# SERDES_10G0 register map
Vendor: Texas Instruments
Registers are 32-bit, read-write, reset 0x0 unless marked. A register's access mark holds for its fields unless they carry their own. Offsets are as the file gives them; [hi:lo] are bit positions; {n}, {i} and the like mark numbered series.

## SERDES_10G0 (part 5 of 5)
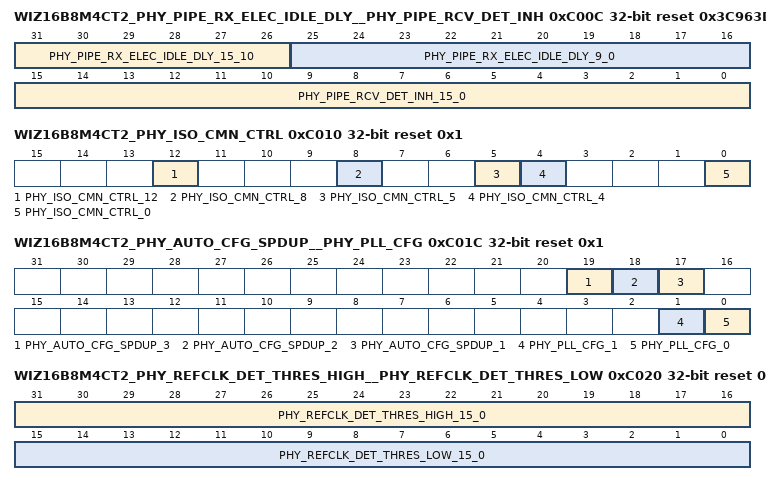
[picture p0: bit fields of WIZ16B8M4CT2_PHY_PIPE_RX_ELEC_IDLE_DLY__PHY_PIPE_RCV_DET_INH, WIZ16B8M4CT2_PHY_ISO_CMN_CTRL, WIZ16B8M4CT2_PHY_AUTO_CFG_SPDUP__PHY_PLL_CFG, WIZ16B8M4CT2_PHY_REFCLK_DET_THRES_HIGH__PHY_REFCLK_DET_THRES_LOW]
0xC00C WIZ16B8M4CT2_PHY_PIPE_RX_ELEC_IDLE_DLY__PHY_PIPE_RCV_DET_INH reset 0x3C963D09 — PIPE receiver detect inhibit register ()
  [31:26] PHY_PIPE_RX_ELEC_IDLE_DLY_15_10 — PCIe PCS L1.x exit Rx electrical idle force fast count : Counter load value to hold PIPE Rx Electrical Idle high upon exit from L1.x. Counter is loaded and starts counting down after phy_l*_rx_elec_idle_det_en is asserted high. Default is 500 nsec. This counter accounts for time to power on just the analog Rx signal detect block. Based on reference clock cycles (25 MHz default). Minimum value = 6'd0.
  [25:16] PHY_PIPE_RX_ELEC_IDLE_DLY_9_0 — PCIe PCS L1.x exit Rx electrical idle force full count : Counter load value to hold PIPE Rx Electrical Idle high upon exit from L1.x when the PMA common was powered down. Counter is loaded and starts counting down upon de-assertion of PMA cmn_ref_clk_disable (upon de-assertion of phy_l*_ent_l1_x for first link). Default is 6 usec. This counter accounts for time to power on the bias and decap and only takes effect if the PMA was suspended. Based on reference clock cycles (25 MHz default). Minimum value = 10'd1.
  [15:0] PHY_PIPE_RCV_DET_INH_15_0 — PCS Receiver Detect Inhibit Counter Load Value: Counter load value to delay receiver detection request to PMA until PMA common mode is within the required range. The timer (running on divided reference clock from PMA) starts once the PMA common has completed startup. If receiver detect request is received while timer has not expired, the PCS will wait until the timer expires before signaling the request to the PMA. Load value is specified in multiples of 4x the divider reference clock period (typically 40 nsec for 100 MHz reference clock input frequency) for a 2.5 msec inhibit time.
0xC010 WIZ16B8M4CT2_PHY_ISO_CMN_CTRL access per field reset 0x1 — PHY common control signal isolation register ()
  [12] PHY_ISO_CMN_CTRL_12 ro — Current value of phy_refclk_reqd PHY output.
  [8] PHY_ISO_CMN_CTRL_8 rw — Drives phy_refclk_en PHY input when in PHY macro and PMA isolation mode.
  [5] PHY_ISO_CMN_CTRL_5 rw — Drives phy_pma_suspend_override PHY input when in PHY macro and PMA isolation mode.
  [4] PHY_ISO_CMN_CTRL_4 rw — Drives refclk_rcvr_pwrdn internal PHY signal when in PHY macro and PMA isolation mode (1 = powers down the reference clock receiver). During normal operation, refclk_rcvr_pwrdn is driven from ~abp_preset_n, which powers down the reference clock receiver when the PHY is disabled.
  [0] PHY_ISO_CMN_CTRL_0 rw — Drives phy_reset_n PHY input when in PHY macro and PMA isolation mode.
0xC014 WIZ16B8M4CT2_PHY_STATE_CHG_TIMEOUT reset 0x30D4 — PHY state change monitor timeout
  [15:0] PHY_STATE_CHG_TIMEOUT_15_0 — State change timeout: Bits [19:4] of the state change timeout (bits [3:0] are zero). The timeout is the maximum number of APB clock cycles (abp_pclk) that are allowed for completion of a PHY power state change for the link. If the timeout expires, phy_interrupt_ln_XX for the associated lane is asserted and interrupt status register bit is set. For maximum allowed APB clock frequency, this provides 5.2 msec maximum timeout. Default is set for 1 msec for the maximum APB clock frequency.
0xC01C WIZ16B8M4CT2_PHY_AUTO_CFG_SPDUP__PHY_PLL_CFG access per field reset 0x1 — PHY speedup control register
  [19] PHY_AUTO_CFG_SPDUP_3 ro — Speedup configuration complete: 1 = PHY speedup configuration is complete, 0 = not complete.
  [18] PHY_AUTO_CFG_SPDUP_2 rw — Speedup configuration stall: 1 = upon completion of PHY speedup configuration, do not release reset to PMA until this bit is cleared, 0 = release reset to PMA upon completion of PHY speedup configuration. Do not set high when [1] = 0.
  [17] PHY_AUTO_CFG_SPDUP_1 rw — Speedup configuration enable: If set to 1 upon de-assertion (high) of phy_reset_n, the PHY will be configured for simulation speedup. Only for use in RTL or gate-level simulations. Not for use in silicon.
  [1] PHY_PLL_CFG_1 rw — PLL configuration: 0 = PHY configured to only use PLL0 / PLL1 disabled. 1 = PHY configured to use both PLL0 and PLL1.
  [0] PHY_PLL_CFG_0 rw — Single link PCIe configuration : 1 = PHY configured such that there is only a single PCIe link (1xN) and all PCIe rates will be driven by PLL0. Any other links are not PCIe and will not use PLL0. 0 = ALl other configurations. This is a static configuration, which can only be changed while phy_reset_n is asserted low.
0xC020 WIZ16B8M4CT2_PHY_REFCLK_DET_THRES_HIGH__PHY_REFCLK_DET_THRES_LOW reset 0x274201C2 — PHY external reference clock detect low threshold register
  [31:16] PHY_REFCLK_DET_THRES_HIGH_15_0 — External Reference Clock Active Detect High Threshold: This is the maximum number of external reference clock cycles which must be counted during the measurement interval to indicate a valid clock detected. The default value is based on 100MHz reference clock frequency and 10 MHZ apb_pclk frequency.
  [15:0] PHY_REFCLK_DET_THRES_LOW_15_0 — External Reference Clock Active Detect Low Threshold: This is the minimum number of external reference clock cycles which must be counted during the measurement interval to indicate a valid clock detected. The default value is based on 100MHz reference clock external frequency and 200 MHz (max) apb_pclk frequency.
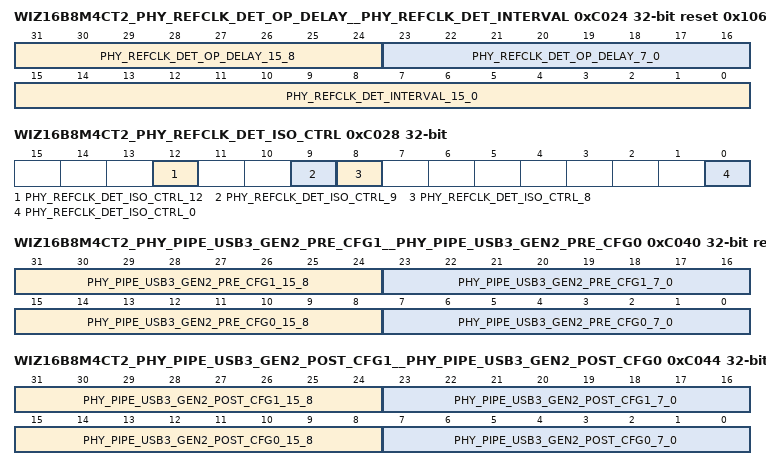
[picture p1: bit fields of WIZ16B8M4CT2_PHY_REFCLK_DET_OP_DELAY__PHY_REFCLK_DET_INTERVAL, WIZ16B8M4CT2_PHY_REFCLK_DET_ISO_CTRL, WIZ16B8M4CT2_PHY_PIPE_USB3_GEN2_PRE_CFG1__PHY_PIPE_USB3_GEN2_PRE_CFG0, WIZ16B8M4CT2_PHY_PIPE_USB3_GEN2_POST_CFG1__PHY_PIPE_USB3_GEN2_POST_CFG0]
0xC024 WIZ16B8M4CT2_PHY_REFCLK_DET_OP_DELAY__PHY_REFCLK_DET_INTERVAL reset 0x106403E8 — PHY external reference clock detect measurement interval register
  [31:24] PHY_REFCLK_DET_OP_DELAY_15_8 — External Reference Clock Active Detect End Delay: This is the number of apb_pclk cycles to wait upon completion of measurement interval before capturing the result (accounts for synchronization delays).
  [23:16] PHY_REFCLK_DET_OP_DELAY_7_0 — External Reference Clock Active Detect Start Delay: This is the number of apb_pclk cycles to wait prior to start of measurement interval (accounts for enable delay of reference clock in PMA).
  [15:0] PHY_REFCLK_DET_INTERVAL_15_0 — External Reference Clock Active Detect Measurement Interval: This is the number of apb_pclk cycles in which to count external reference clock cycles. The default corresponds to 5 us for 200 MHz apb_clk and 100 us for 10 MHz apb_clock.
0xC028 WIZ16B8M4CT2_PHY_REFCLK_DET_ISO_CTRL access per field — PHY external reference clock detect isolation control register
  [12] PHY_REFCLK_DET_ISO_CTRL_12 ro — Captures the current value of the pma_cmn_ext_refclk_detected_cfg PHY input.
  [9] PHY_REFCLK_DET_ISO_CTRL_9 ro — Current value of pma_cmn_ext_refclk_detected PHY output.
  [8] PHY_REFCLK_DET_ISO_CTRL_8 ro — Current value of pma_cmn_ext_refclk_detected_valid PHY output.
  [0] PHY_REFCLK_DET_ISO_CTRL_0 wo — External Reference Clock Active Detect Start: Write with 1 to initiate an external reference clock active detect operation. Any previous operation must have completed prior to writing with 1.
0xC040 WIZ16B8M4CT2_PHY_PIPE_USB3_GEN2_PRE_CFG1__PHY_PIPE_USB3_GEN2_PRE_CFG0 reset 0xA0A — PHY USB3 Gen 2 pre-shoot configuration 0 register ()
  [31:24] PHY_PIPE_USB3_GEN2_PRE_CFG1_15_8 — USB3 Gen 2 transmit pre-shoot multiplier configuration 3: For a lane configured for USB3 mode at Gen 3 data rate, sets the multiplier configuration for the Tx de-emphasis pre-shoot (C-1) when pipe_lXX_tx_deemphasis[1:0] == 0b11 for the associated lane. Default: 0.
  [23:16] PHY_PIPE_USB3_GEN2_PRE_CFG1_7_0 — USB3 Gen 2 transmit pre-shoot multiplier configuration 2: For a lane configured for USB3 mode at Gen 3 data rate, sets the multiplier configuration for the Tx de-emphasis pre-shoot (C1) when pipe_lXX_tx_deemphasis[1:0] == 0b10 for the associated lane. Default: 0.
  [15:8] PHY_PIPE_USB3_GEN2_PRE_CFG0_15_8 — USB3 Gen 2 transmit pre-shoot multiplier configuration 1: For a lane configured for USB3 mode at Gen 3 data rate, sets the multiplier configuration for the Tx de-emphasis pre-shoot (C-1) when pipe_lXX_tx_deemphasis[1:0] == 0b01 for the associated lane. Default: 5/64.
  [7:0] PHY_PIPE_USB3_GEN2_PRE_CFG0_7_0 — USB3 Gen 2 transmit pre-shoot multiplier configuration 0: For a lane configured for USB3 mode at Gen 3 data rate, sets the multiplier configuration for the Tx de-emphasis pre-shoot (C-1) when pipe_lXX_tx_deemphasis[1:0] == 0b00 for the associated lane. The multiplier is set based on: Default: 5/64.
0xC044 WIZ16B8M4CT2_PHY_PIPE_USB3_GEN2_POST_CFG1__PHY_PIPE_USB3_GEN2_POST_CFG0 reset 0x101000 — PHY USB3 Gen 2 de-emphasis configuration 0 register ()
  [31:24] PHY_PIPE_USB3_GEN2_POST_CFG1_15_8 — USB3 Gen 2 transmit pre-shoot multiplier configuration 3: For a lane configured for USB3 mode at Gen 3 data rate, sets the multiplier configuration for the Tx de-emphasis (C1) when pipe_lXX_tx_deemphasis[1:0] == 0b11 for the associated lane. Default: 0.
  [23:16] PHY_PIPE_USB3_GEN2_POST_CFG1_7_0 — USB3 Gen 2 transmit pre-shoot multiplier configuration 2: For a lane configured for USB3 mode at Gen 3 data rate, sets the multiplier configuration for the Tx de-emphasis (C1) when pipe_lXX_tx_deemphasis[1:0] == 0b10 for the associated lane. Default: 1/8.
  [15:8] PHY_PIPE_USB3_GEN2_POST_CFG0_15_8 — USB3 Gen 2 transmit pre-shoot multiplier configuration 1: For a lane configured for USB3 mode at Gen 3 data rate, sets the multiplier configuration for the Tx de-emphasis (C1) when pipe_lXX_tx_deemphasis[1:0] == 0b01 for the associated lane. Default: 1/8.
  [7:0] PHY_PIPE_USB3_GEN2_POST_CFG0_7_0 — USB3 Gen 2 transmit pre-shoot multiplier configuration 0: For a lane configured for USB3 mode at Gen 3 data rate, sets the multiplier configuration for the Tx de-emphasis (C1) when pipe_lXX_tx_deemphasis[1:0] == 0b00 for the associated lane. Default: 0.
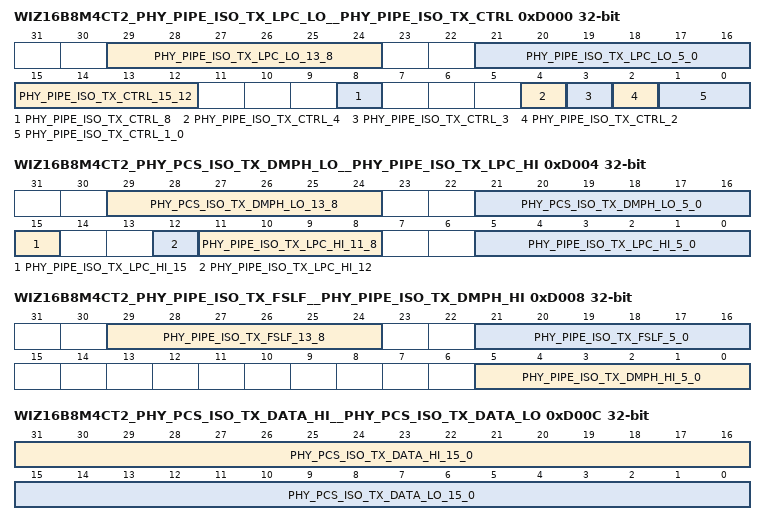
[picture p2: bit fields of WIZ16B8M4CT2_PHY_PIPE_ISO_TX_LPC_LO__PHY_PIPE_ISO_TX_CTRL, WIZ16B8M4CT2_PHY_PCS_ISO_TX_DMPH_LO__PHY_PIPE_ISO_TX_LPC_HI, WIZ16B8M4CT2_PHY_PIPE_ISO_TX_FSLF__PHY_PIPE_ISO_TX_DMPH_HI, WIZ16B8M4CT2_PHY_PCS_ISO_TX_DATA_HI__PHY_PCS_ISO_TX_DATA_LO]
0xD000 WIZ16B8M4CT2_PHY_PIPE_ISO_TX_LPC_LO__PHY_PIPE_ISO_TX_CTRL access per field — PIPE TX control signal isolation register ()
  [29:24] PHY_PIPE_ISO_TX_LPC_LO_13_8 ro — Current value of pipe_tx_local_tx_preset_coefficients[11:6] for the associated lane when PHY_PCS_ISO_TX_LPC_HI[15] == 1. Otherwise, 0.
  [21:16] PHY_PIPE_ISO_TX_LPC_LO_5_0 ro — Current value of pipe_tx_local_tx_preset_coefficients[5:0] for the associated lane when PHY_PCS_ISO_TX_LPC_HI[15] == 1. Otherwise, 0.
  [15:12] PHY_PIPE_ISO_TX_CTRL_15_12 rw — Drives pipe_tx_data_k PHY input for the associated lane when in PHY macro and PMA isolation modes.
  [8] PHY_PIPE_ISO_TX_CTRL_8 rw — Drives pipe_tx_ones_zeros input for the associated lane when in PHY macro and PMA isolation modes.
  [4] PHY_PIPE_ISO_TX_CTRL_4 rw — Drives pipe_tx_elec_idle PHY input for the associated lane when in PHY macro and PMA isolation modes
  [3] PHY_PIPE_ISO_TX_CTRL_3 rw — Drives pipe_tx_128b_enc_byp PHY input for the associated lane when in PHY macro and PMA isolation modes.
  [2] PHY_PIPE_ISO_TX_CTRL_2 rw — Drives pipe_tx_compliance PHY input for the associated lane when in PHY macro and PMA isolation modes.
  [1:0] PHY_PIPE_ISO_TX_CTRL_1_0 rw — Drives pipe_tx_pattern PHY input for the associated lane when in PHY macro and PMA isolation modes.
0xD004 WIZ16B8M4CT2_PHY_PCS_ISO_TX_DMPH_LO__PHY_PIPE_ISO_TX_LPC_HI access per field — PIPE TX local preset coefficients high isolation register ()
  [29:24] PHY_PCS_ISO_TX_DMPH_LO_13_8 rw — Drives pipe_tx_deemph[11:6] PHY input for the associated lane when in PHY macro and PMA isolation mode.
  [21:16] PHY_PCS_ISO_TX_DMPH_LO_5_0 rw — Drives pipe_tx_deemph[5:0] PHY input for the associated lane when in PHY macro and PMA isolation mode.
  [15] PHY_PIPE_ISO_TX_LPC_HI_15 ro — Set upon assertion of pipe_tx_local_tx_coeff_vld PHY output for the associated lane. Cleared upon writing PHY_PCS_ISO_TX_LPC_HI[12] with a 0.
  [12] PHY_PIPE_ISO_TX_LPC_HI_12 rw — Drives pipe_tx_get_local_preset_coef PHY output for the associated lane when in PHY macro and PMA isolation modes
  [11:8] PHY_PIPE_ISO_TX_LPC_HI_11_8 rw — Drives pipe_tx_local_preset_index PHY output for the associated lane when in PHY macro and PMA isolation modes.
  [5:0] PHY_PIPE_ISO_TX_LPC_HI_5_0 ro — Current value of pipe_tx_local_tx_preset_coefficients[17:12] for the associated lane when PHY_PCS_ISO_TX_LPC_HI[15] == 1. Otherwise, 0.
0xD008 WIZ16B8M4CT2_PHY_PIPE_ISO_TX_FSLF__PHY_PIPE_ISO_TX_DMPH_HI access per field — PIPE TX deemphasis high isolation register ()
  [29:24] PHY_PIPE_ISO_TX_FSLF_13_8 ro — Current value of pipe_tx_local_fs PHY output for the associated lane. (Not re-synchronized to apb_pclk)
  [21:16] PHY_PIPE_ISO_TX_FSLF_5_0 ro — Current value of pipe_tx_local_lf PHY output for the associated lane. (Not re-synchronized to apb_pclk)
  [5:0] PHY_PIPE_ISO_TX_DMPH_HI_5_0 rw — Drives pipe_tx_deemph[17:12] PHY input for the associated lane when in PHY macro and PMA isolation modes.
0xD00C WIZ16B8M4CT2_PHY_PCS_ISO_TX_DATA_HI__PHY_PCS_ISO_TX_DATA_LO — PCS TX PIPE data low isolation register ()
  [31:16] PHY_PCS_ISO_TX_DATA_HI_15_0 — Drives pipe_tx_data[31:16] PHY input for the associated lane when in PHY macro and PMA isolation mode.
  [15:0] PHY_PCS_ISO_TX_DATA_LO_15_0 — Drives pipe_tx_data[15:0] PHY input for the associated lane when in PHY macro and PMA isolation mode.
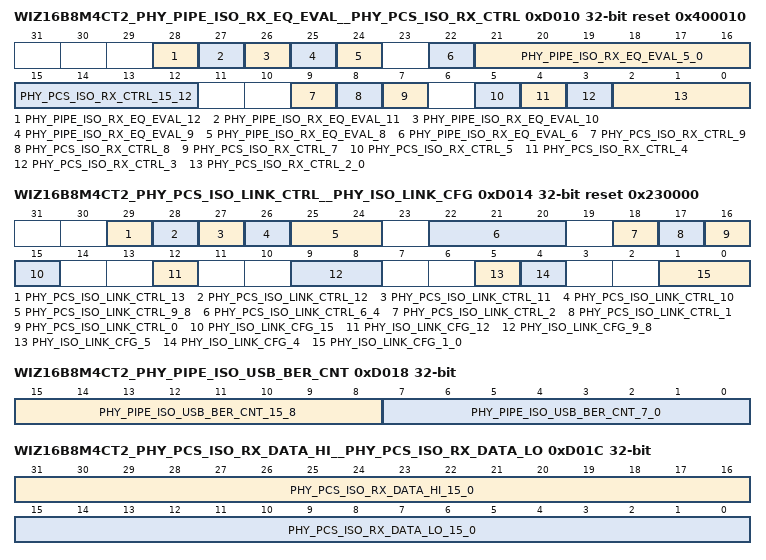
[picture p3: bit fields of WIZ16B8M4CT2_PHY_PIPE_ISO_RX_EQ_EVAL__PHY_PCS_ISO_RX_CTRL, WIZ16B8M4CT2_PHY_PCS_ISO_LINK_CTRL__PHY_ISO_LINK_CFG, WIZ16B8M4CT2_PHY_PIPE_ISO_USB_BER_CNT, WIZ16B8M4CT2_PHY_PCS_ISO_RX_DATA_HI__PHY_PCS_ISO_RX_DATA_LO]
0xD010 WIZ16B8M4CT2_PHY_PIPE_ISO_RX_EQ_EVAL__PHY_PCS_ISO_RX_CTRL access per field reset 0x400010 — PCS RX control signal isolation register ()
  [28] PHY_PIPE_ISO_RX_EQ_EVAL_12 rw — Drives pipe_invalid_request for the associated lane when in PHY macro and PMA isolation modes.
  [27] PHY_PIPE_ISO_RX_EQ_EVAL_11 rw — pipe_link_eval_dir_change[5:4] bit reversal enable. When low, no bit reversal. When high, the bit positions for pipe_link_eval_dir_change[5:4] PHY output for the associated lane are reversed.
  [26] PHY_PIPE_ISO_RX_EQ_EVAL_10 rw — pipe_link_eval_dir_change[3:2] bit reversal enable. When low, no bit reversal. When high, the bit positions for pipe_link_eval_dir_change[3:2] PHY output for the associated lane are reversed.
  [25] PHY_PIPE_ISO_RX_EQ_EVAL_9 rw — pipe_link_eval_dir_change[1:0] bit reversal enable. When low, no bit reversal. When high, the bit positions for pipe_link_eval_dir_change[1:0] PHY output for the associated lane are reversed.]
  [24] PHY_PIPE_ISO_RX_EQ_EVAL_8 rw — Drives pipe_rx_eval PHY input for the associated lane when in PHY macro and PMA isolation modes.
  [22] PHY_PIPE_ISO_RX_EQ_EVAL_6 ro — Captures pipe_phy_status for Rx equalization evaluation PHY output for the associated lane (does not include power state change signaling). Set when pipe_phy_status is high and pipe_rx_eq_eval to the PCS is high (i.e. after the isolation MUX). Cleared upon read.
  [21:16] PHY_PIPE_ISO_RX_EQ_EVAL_5_0 ro — pipe_link_eval_dir_change PHY output for the associated lane (prior to bit reversal logic) upon completion of Rx equalization evaluation. Captured upon assertion of Rx equalization eval pipe_phy_status when pipe_rx_eq_eval to the PCS (i.e. after the isolation MUX) is high. Cleared upon read. (Not re-synchronized to apb_pclk)
  [15:12] PHY_PCS_ISO_RX_CTRL_15_12 ro — Current value of pipe_rx_data_k PHY output for the associated lane, when PHY_PCS_ISO_RX_CTRL[5] == 1. Otherwise, 0. (Not re-synchronized to apb_pclk)
  [9] PHY_PCS_ISO_RX_CTRL_9 rw — Drives pipe_rx_eq_training PHY input for the associated lane when in PHY macro and PMA isolation modes.
  [8] PHY_PCS_ISO_RX_CTRL_8 rw — Drives pipe_rx_termination PHY input for the associated lane when in PHY macro and PMA isolation modes.
  [7] PHY_PCS_ISO_RX_CTRL_7 rw — Drives pipe_rx_polarity PHY input for the associated lane when in PHY macro and PMA isolation modes.
  [5] PHY_PCS_ISO_RX_CTRL_5 ro — Current value of pipe_rx_valid PHY output for the associated lane.
  [4] PHY_PCS_ISO_RX_CTRL_4 ro — Current value of pipe_rx_elec_idle PHY output for the associated lane.
  [3] PHY_PCS_ISO_RX_CTRL_3 ro — Current value of pipe_align_detect PHY output for the associated lane.
  [2:0] PHY_PCS_ISO_RX_CTRL_2_0 ro — Current value of pipe_rx_status PHY output for the associated lane. Holds the highest priority pipe_rx_status value seen, since the last register read. Cleared upon read.
0xD014 WIZ16B8M4CT2_PHY_PCS_ISO_LINK_CTRL__PHY_ISO_LINK_CFG access per field reset 0x230000 — PHY link configuration isolation register
  [29] PHY_PCS_ISO_LINK_CTRL_13 ro — Current value of phy_l*_ack_l1_x PHY output for the associated lane. ()
  [28] PHY_PCS_ISO_LINK_CTRL_12 rw — Drives the phy_l*_ent_l1_x PHY input for the associated lane when in PHY macro and PMA isolation modes. (Link signal - for multi-lane links, master lane used for all lanes in link.)
  [27] PHY_PCS_ISO_LINK_CTRL_11 rw — Drives the phy_l*_rx_elec_idle_det_en PHY input for the associated lane when in PHY macro and PMA isolation modes. (Link signal - for multi-lane links, master lane used for all lanes in link.)
  [26] PHY_PCS_ISO_LINK_CTRL_10 rw — Drives the phy_l*_tx_cmn_mode_en PHY input for the associated lane when in PHY macro and PMA isolation modes. (Link signal - for multi-lane links, master lane used for all lanes in link.)
  [25:24] PHY_PCS_ISO_LINK_CTRL_9_8 rw — Drives the pipe_l*_rate PHY input for the associated lane when in PHY macro and PMA isolation modes. (Link signal - for multi-lane links, master lane used for all lanes in link.)
  [22:20] PHY_PCS_ISO_LINK_CTRL_6_4 rw — Drives the pipe_l*_powerdown PHY input for the associated lane when in PHY macro and PMA isolation modes. (Link signal - for multi-lane links, master lane used for all lanes in link.)
  [18] PHY_PCS_ISO_LINK_CTRL_2 rw — Drives the pipe_l*_tx_det_rx_lpbk PHY input for the associated lane when in PHY macro and PMA isolation modes. (Link signal - for multi-lane links, master lane used for all lanes in link.)
  [17] PHY_PCS_ISO_LINK_CTRL_1 ro — Captures pipe_l*_phy_status (for power state and rate change) PHY output for the associated lane. Set when pipe_phy_status is high and cleared upon read if pipe_phy_status is low. ()
  [16] PHY_PCS_ISO_LINK_CTRL_0 rw — Drives the phy_l*_reset_n PHY input for the associated lane when in PHY macro and PMA isolation modes. (Link signal - for multi-lane links, master lane used for all lanes in link.)
  [15] PHY_ISO_LINK_CFG_15 rw — Drives phy_link_cfg_ln_{nnnn} PHY input when in PHY macro and PMA isolation modes.
  [12] PHY_ISO_LINK_CFG_12 rw — Drives pipe_l{nnnn}_32bit_sel PHY input when in PHY macro and PMA isolation modes.
  [9:8] PHY_ISO_LINK_CFG_9_8 rw — Drives pma_fullrt_div_ln_{nnnn} PHY input when in PHY macro and PMA isolation modes.
  [5] PHY_ISO_LINK_CFG_5 rw — Drives pipe_l{nnnn}_pcie_l1_ss_sel PHY input when in PHY macro and PMA isolation mode.
  [4] PHY_ISO_LINK_CFG_4 rw — Drives pipe_l{nnnn}_eb_mode PHY input when in PHY macro and PMA isolation modes.
  [1:0] PHY_ISO_LINK_CFG_1_0 rw — Drives phy_l{nnnn}_mode PHY input when in PHY macro and PMA isolation modes.
0xD018 WIZ16B8M4CT2_PHY_PIPE_ISO_USB_BER_CNT ro — PIPE USB Gen 1 loopback slave BER count register ()
  [15:8] PHY_PIPE_ISO_USB_BER_CNT_15_8 — Reerved
  [7:0] PHY_PIPE_ISO_USB_BER_CNT_7_0 — Current value of USB 3.1 Gen 1 loopback slave Bit Error Count from the PCS.
0xD01C WIZ16B8M4CT2_PHY_PCS_ISO_RX_DATA_HI__PHY_PCS_ISO_RX_DATA_LO ro — PCS RX data low isolation register ()
  [31:16] PHY_PCS_ISO_RX_DATA_HI_15_0 — Current value of pipe_rx_data[31:16] PHY output. (Not re-synchronized to apb_pclk)
  [15:0] PHY_PCS_ISO_RX_DATA_LO_15_0 — Current value of pipe_rx_data[15:0] PHY output. (Not re-synchronized to apb_pclk)
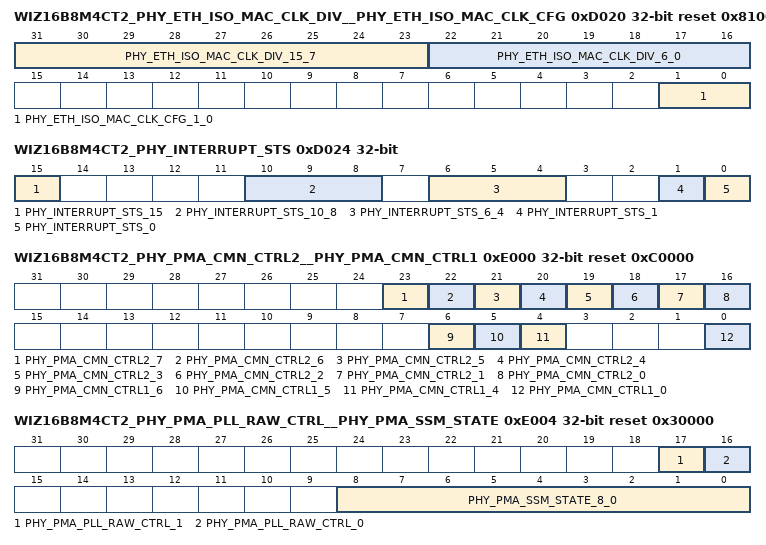
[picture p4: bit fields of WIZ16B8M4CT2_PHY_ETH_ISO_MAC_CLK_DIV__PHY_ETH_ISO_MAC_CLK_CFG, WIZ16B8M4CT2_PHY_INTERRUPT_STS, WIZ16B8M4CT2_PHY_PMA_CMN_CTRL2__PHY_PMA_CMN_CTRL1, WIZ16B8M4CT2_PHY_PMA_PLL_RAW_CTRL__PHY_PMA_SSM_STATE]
0xD020 WIZ16B8M4CT2_PHY_ETH_ISO_MAC_CLK_DIV__PHY_ETH_ISO_MAC_CLK_CFG reset 0x810000 — Ethernet MAC clock configuration isolation register
  [31:23] PHY_ETH_ISO_MAC_CLK_DIV_15_7 — Drives mac_div_sel1 PHY input for the associated lane when in PHY macro and PMA isolation mode.
  [22:16] PHY_ETH_ISO_MAC_CLK_DIV_6_0 — Drives mac_div_sel0 PHY input for the associated lane when in PHY macro and PMA isolation mode.
  [1:0] PHY_ETH_ISO_MAC_CLK_CFG_1_0 — Drives mac_src_sel PHY input for the associated lane when in PHY macro and PMA isolation mode.
0xD024 WIZ16B8M4CT2_PHY_INTERRUPT_STS access per field — PHY interrupt status register
  [15] PHY_INTERRUPT_STS_15 rw — State change monitor enable - 1 = state change monitor enabled, 0 = state change monitor disabled. Note: Only the master lane's state change monitor for a link is enabled. The state change monitor for a slave lane is disabled regardless of the state of this bit.
  [10:8] PHY_INTERRUPT_STS_10_8 ro — Next power state/data rate - Only valid when one of the interrupt status bits is set. Indicates the requested power state or data rate for the state change failure. For PIPE requests, loaded based on the following: For Raw SerDes power state change requests, loaded based on following:
  [6:4] PHY_INTERRUPT_STS_6_4 ro — Current power state/data rate - Only valid when one of the interrupt status bits is set. Indicates the starting power state or data rate for the state change failure. For PIPE requests, loaded based on the following: For Raw SerDes power state change requests, loaded based on following:
  [1] PHY_INTERRUPT_STS_1 rw — Data rate state change interrupt status - Set to 1 upon data rate change timeout. Cleared upon read. Bit is writeable to allow the interrupt to be set manually for test purposes.Only set high by data rate change timeout if bit[0] == 0.
  [0] PHY_INTERRUPT_STS_0 rw — Power state change interrupt status - Set to 1 upon power state change timeout. Cleared upon read. Bit is writeable to allow the interrupt to set manually for test purposes. Only set high by power state change timeout if bit[1] == 0.
0xE000 WIZ16B8M4CT2_PHY_PMA_CMN_CTRL2__PHY_PMA_CMN_CTRL1 access per field reset 0xC0000 — PMA common control1 register
  [23] PHY_PMA_CMN_CTRL2_7 ro — Current value of cmn_pll1_locked PMA output
  [22] PHY_PMA_CMN_CTRL2_6 ro — Current value of cmn_pll0_locked PMA output
  [21] PHY_PMA_CMN_CTRL2_5 ro — Current value of cmn_pll1_clk_en_ack PMA output
  [20] PHY_PMA_CMN_CTRL2_4 ro — Current value of cmn_pll0_clk_en_ack PMA output
  [19] PHY_PMA_CMN_CTRL2_3 ro — Current value of cmn_pll1_disabled PMA output
  [18] PHY_PMA_CMN_CTRL2_2 ro — Current value of cmn_pll0_disabled PMA output
  [17] PHY_PMA_CMN_CTRL2_1 ro — Current value of cmn_pll1_ready PMA output
  [16] PHY_PMA_CMN_CTRL2_0 ro — Current value of cmn_pll0_ready PMA output
  [6] PHY_PMA_CMN_CTRL1_6 rw — Drives cmn_refclk_rcv_out_en PMA input
  [5] PHY_PMA_CMN_CTRL1_5 ro — Current value of cmn_macro_suspend_ack PMA output
  [4] PHY_PMA_CMN_CTRL1_4 ro — Current value of cmn_refclk_active PMA output
  [0] PHY_PMA_CMN_CTRL1_0 ro — Current value of cmn_ready pin PMA output
0xE004 WIZ16B8M4CT2_PHY_PMA_PLL_RAW_CTRL__PHY_PMA_SSM_STATE access per field reset 0x30000 — PMA SSM current state register
  [17] PHY_PMA_PLL_RAW_CTRL_1 rw — Raw SerDes PLL1 control : When set to 1, cmn_pll1_en PMA input is controlled by PHY logic. When set to 0, cmn_pll1_en PMA input is forced low. When PLL1 is driving lanes configured for Raw SerDes operation, this bit allows manual' enable/disable of PLL1 to allow reconfiguration of the PLL for a different data rate. The PHY logic drives cmn_pll1_en high unless the PHY is configured to operation on PLL0 only (PHY_PLL_CFG[1] == 0).
  [16] PHY_PMA_PLL_RAW_CTRL_0 rw — Raw SerDes PLL0 control : When set to 1, cmn_pll0_en PMA input is controlled by PHY logic. When set to 0, cmn_pll0_en PMA input is forced low. When PLL0 is driving lanes configured for Raw SerDes operation, this bit allows manual' enable/disable of PLL0 to allow reconfiguration of the PLL for a different data rate. The PHY logic drives cmn_pll0_en high except when the PHY is configured for single link PCIe mode and is performing a rate change between PCIe Gen 1/2 and PCIe Gen 3 (PHY_PLL_CFG[0] == 1). However, PCIe is only supported for PIPE mode and not applicable when PLL0 is driving lanes configured for Raw SerDes operation.
  [8:0] PHY_PMA_SSM_STATE_8_0 ro — PMA SSM : Current state of the PMA startup state machine. PMA output (Not re-synchronized to apb_pclk)
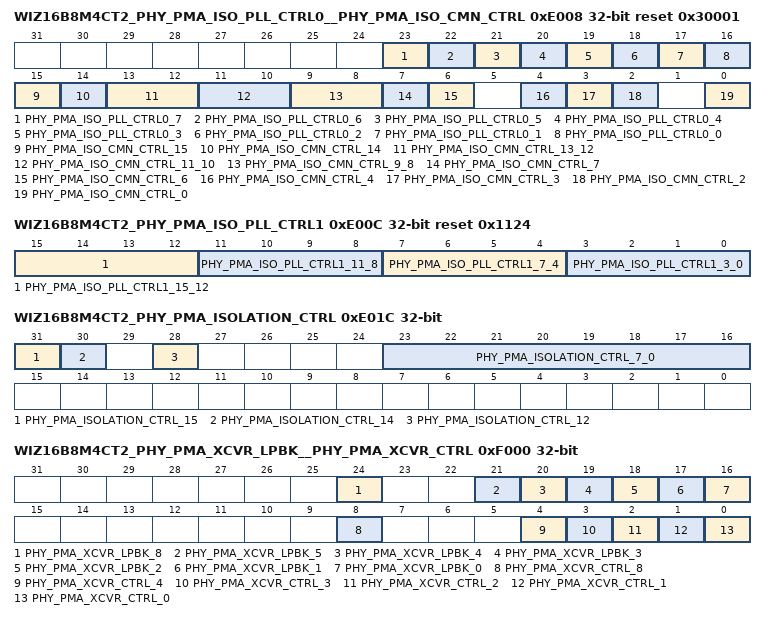
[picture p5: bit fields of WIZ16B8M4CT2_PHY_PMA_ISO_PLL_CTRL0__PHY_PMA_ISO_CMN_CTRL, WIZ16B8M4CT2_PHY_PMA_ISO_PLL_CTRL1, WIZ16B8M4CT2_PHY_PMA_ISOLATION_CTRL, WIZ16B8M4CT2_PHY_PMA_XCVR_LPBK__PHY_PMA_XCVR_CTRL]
0xE008 WIZ16B8M4CT2_PHY_PMA_ISO_PLL_CTRL0__PHY_PMA_ISO_CMN_CTRL access per field reset 0x30001 — PMA common control signal isolation register
  [23] PHY_PMA_ISO_PLL_CTRL0_7 rw — Drives cmn_pll1_ref_clk_sel PMA input when in PHY macro or PMA isolation mode.
  [22] PHY_PMA_ISO_PLL_CTRL0_6 rw — Drives cmn_pll0_ref_clk_sel PMA input when in PHY macro or PMA isolation mode.
  [21] PHY_PMA_ISO_PLL_CTRL0_5 rw — Drives cmn_pll1_mode_sel PMA input when in PMA isolation mode.
  [20] PHY_PMA_ISO_PLL_CTRL0_4 rw — Drives cmn_pll0_mode_sel PMA input when in PMA isolation mode.
  [19] PHY_PMA_ISO_PLL_CTRL0_3 rw — Drives cmn_pll1_clk_en PMA input when in PMA isolation mode
  [18] PHY_PMA_ISO_PLL_CTRL0_2 rw — Drives cmn_pll0_clk_en PMA input when in PMA isolation mode
  [17] PHY_PMA_ISO_PLL_CTRL0_1 rw — Drives cmn_pll1_en PMA input when in PMA isolation mode
  [16] PHY_PMA_ISO_PLL_CTRL0_0 rw — Drives cmn_pll0_en PMA input when in PMA isolation mode
  [15] PHY_PMA_ISO_CMN_CTRL_15 rw — Drives cmn_ref_clk_term_en PMA input when in PHY macro or PMA isolation modes
  [14] PHY_PMA_ISO_CMN_CTRL_14 rw — Drives cmn_ref_clk_dig_sel PMA input when in PHY macro or PMA isolation modes
  [13:12] PHY_PMA_ISO_CMN_CTRL_13_12 rw — Drives cmn_ref_clk_dig_div PMA input when in PHY macro or PMA isolation modes
  [11:10] PHY_PMA_ISO_CMN_CTRL_11_10 rw — Drives cmn_ref_clk_int_mode PMA input when in PHY macro and PMA isolation modes.
  [9:8] PHY_PMA_ISO_CMN_CTRL_9_8 rw — Drives cmn_ref_clk0_mode PMA input when in PHY macro and PMA isolation modes.
  [7] PHY_PMA_ISO_CMN_CTRL_7 ro — Current value of cmn_clock_stop_ack PMA output.
  [6] PHY_PMA_ISO_CMN_CTRL_6 rw — Drives cmn_clock_stop_req PMA input when in PMA isolation mode
  [4] PHY_PMA_ISO_CMN_CTRL_4 rw — Drives cmn_ref_clk0_clk_gate_en PMA input when in PMA isolation mode.
  [3] PHY_PMA_ISO_CMN_CTRL_3 rw — Drives cmn_refclk_disable PMA input when in PMA isolation mode.
  [2] PHY_PMA_ISO_CMN_CTRL_2 rw — Drives cmn_macro_suspend_req PMA input when in PMA isolation mode.
  [0] PHY_PMA_ISO_CMN_CTRL_0 rw — Drives cmn_reset_n PMA input when in PMA isolation mode.
0xE00C WIZ16B8M4CT2_PHY_PMA_ISO_PLL_CTRL1 reset 0x1124 — PMA PLL control1 isolation register
  [15:12] PHY_PMA_ISO_PLL_CTRL1_15_12 — Drives cmn_pll1_clk_datart1_div PMA input when in PMA isolation mode
  [11:8] PHY_PMA_ISO_PLL_CTRL1_11_8 — Drives cmn_pll1_clk_datart0_div PMA input when in PMA isolation mode
  [7:4] PHY_PMA_ISO_PLL_CTRL1_7_4 — Drives cmn_pll0_clk_datart1_div PMA input when in PMA isolation mode
  [3:0] PHY_PMA_ISO_PLL_CTRL1_3_0 — Drives cmn_pll0_clk_datart0_div PMA input when in PMA isolation mode
0xE014 WIZ16B8M4CT2_PHY_PMA_PLL0_SM_STATE ro reset 0x3000000 — PMA PLL0 State Machine current state register
  [27:16] PHY_PMA_PLL0_SM_STATE_11_0 — Current value of cmn_pllsm0_state[11:0]. PMA output (Debug only: Not re-synchronized)
0xE018 WIZ16B8M4CT2_PHY_PMA_PLL1_SM_STATE ro reset 0x300 — PMA PLL1 State Machine current state register
  [11:0] PHY_PMA_PLL1_SM_STATE_11_0 — Current value of cmn_pllsm1_state[11:0]. PMA output (Debug only: Not re-synchronized)
0xE01C WIZ16B8M4CT2_PHY_PMA_ISOLATION_CTRL — PMA Isolation control register
  [31] PHY_PMA_ISOLATION_CTRL_15 — PHY/PMA isolation enable (isolation_en) - When set, enables isolation (PHY or PMA).
  [30] PHY_PMA_ISOLATION_CTRL_14 — PHY/PMA common isolation enable (cmn_isolation_en) - When in PHY Macro Isolation Mode, the PHY common isolation register(s) are selected. When in PMA Isolation Mode, the PMA common isolation register(s) are selected.
  [28] PHY_PMA_ISOLATION_CTRL_12 — PHY/PMA isolation mode select (isolation_mode_sel) - When isolation_en is set, this bit selects between PHY isolation mode and PMA isolation mode. 0 = PHYMacro isolation mode; 1 = PMA isolation mode.
  [23:16] PHY_PMA_ISOLATION_CTRL_7_0 — PHY/PMA lane isolation enable (ln_isolation_en) - When in PHY Macro Isolation Mode, the selected PHY lane(s) isolation registers are selected. When in PMA Isolation Mode, the selected PMA lane(s) isolation registers are selected.
0xF000 WIZ16B8M4CT2_PHY_PMA_XCVR_LPBK__PHY_PMA_XCVR_CTRL access per field — PMA transceiver control register
  [24] PHY_PMA_XCVR_LPBK_8 rw — Drives the tx_bist_hold PMA input for all lanes in the associated link (i.e. the bit associated with the master lane of the link drives all lanes in the link). Synchronized to transmit data rate clock.
  [21] PHY_PMA_XCVR_LPBK_5 rw — Drives the xcvr_lpbk_fe_parallel_en PMA input for the associated lane.
  [20] PHY_PMA_XCVR_LPBK_4 rw — Drives the xcvr_lpbk_ne_parallel_en PMA input for the associated lane.
  [19] PHY_PMA_XCVR_LPBK_3 rw — Drives the xcvr_lpbk_recovered_clk_en PMA input for the associated lane.
  [18] PHY_PMA_XCVR_LPBK_2 rw — Drives the xcvr_lpbk_line_en PMA input for the associated lane.
  [17] PHY_PMA_XCVR_LPBK_1 rw — Drives the xcvr_lpbk_isi_gen_en PMA input for the associated lane.
  [16] PHY_PMA_XCVR_LPBK_0 rw — Drives the xcvr_lpbk_serial_en PMA input for the associated lane.
  [8] PHY_PMA_XCVR_CTRL_8 rw — Drives the tx_differential_invert PMA input for the associated lane.
  [4] PHY_PMA_XCVR_CTRL_4 ro — Current value of rx_cdrlf_fphl_locked PMA output for the associated lane.
  [3] PHY_PMA_XCVR_CTRL_3 ro — Current value of rx_bist_status PMA output for the associated lane.
  [2] PHY_PMA_XCVR_CTRL_2 ro — Current value of rx_bist_err_toggle PMA output for the associated lane.
  [1] PHY_PMA_XCVR_CTRL_1 ro — Current value of rx_bist_sync PMA output for the associated lane.
  [0] PHY_PMA_XCVR_CTRL_0 rw — Drives the rx_differential_invert PMA input for the associated lane.
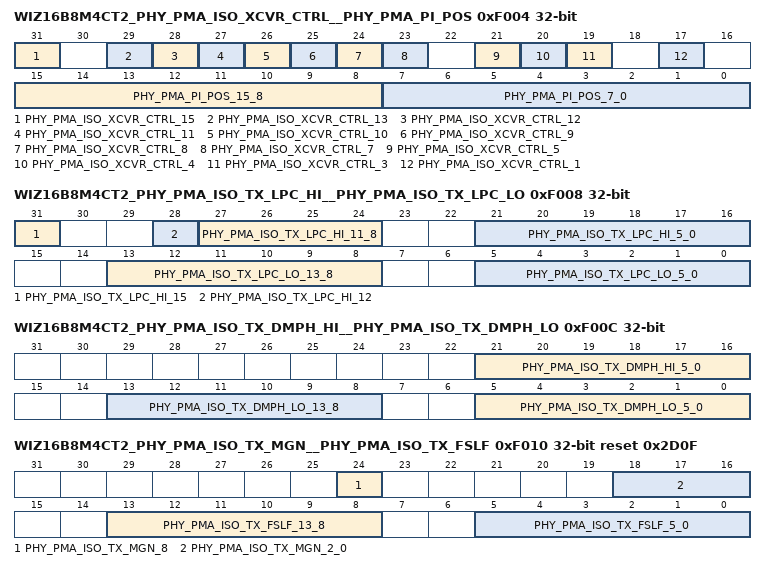
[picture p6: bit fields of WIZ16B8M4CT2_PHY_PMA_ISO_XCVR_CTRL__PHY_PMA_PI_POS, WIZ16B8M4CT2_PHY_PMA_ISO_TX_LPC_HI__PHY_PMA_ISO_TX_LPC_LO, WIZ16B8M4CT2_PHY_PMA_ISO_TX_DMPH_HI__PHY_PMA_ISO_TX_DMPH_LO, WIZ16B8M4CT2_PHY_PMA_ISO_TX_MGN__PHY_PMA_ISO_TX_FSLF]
0xF004 WIZ16B8M4CT2_PHY_PMA_ISO_XCVR_CTRL__PHY_PMA_PI_POS access per field — PMA Transceiver control isolation register
  [31] PHY_PMA_ISO_XCVR_CTRL_15 ro — Current value of xcvr_pll_clk_en_ack PMA output for the associated lane.
  [29] PHY_PMA_ISO_XCVR_CTRL_13 rw — Drives tx_lfps_en PMA input for the associated lane when in PMA isolation mode.
  [28] PHY_PMA_ISO_XCVR_CTRL_12 rw — Drives tx_elec_idle PMA input for the associated lane when in PMA isolation mode or PHY isolation mode and lane is configured for Raw SerDes mode.
  [27] PHY_PMA_ISO_XCVR_CTRL_11 ro — Current value of tx_rcv_detected PMA output for the associated lane. (Not re-synchronized to apb_pclk)
  [26] PHY_PMA_ISO_XCVR_CTRL_10 ro — Current value of tx_rcv_detect_done PMA ouptut for the associated lane.
  [25] PHY_PMA_ISO_XCVR_CTRL_9 rw — Drives tx_rcv_detect_en PMA input for the associated lane when in PMA isolation mode or PHY isolation mode and lane is configured for Raw SerDes mode.
  [24] PHY_PMA_ISO_XCVR_CTRL_8 rw — Drives xcvr_link_reset_n PMA input for the associated lane when in PMA isolation mode.
  [23] PHY_PMA_ISO_XCVR_CTRL_7 rw — Drives xcvr_pll_clk_en PMA input for the associated lane when in PMA isolation mode or PHY isolation mode and lane is configured for Raw SerDes mode.
  [21] PHY_PMA_ISO_XCVR_CTRL_5 rw — Drives xcvr_lane_suspend PMA input for the associated lane when in PMA isolation mode.
  [20] PHY_PMA_ISO_XCVR_CTRL_4 ro — Current value of rx_lfps_detect PMA output for the associated lane.
  [19] PHY_PMA_ISO_XCVR_CTRL_3 ro — Current value of rx_signal_detect PMA output for the associated lane.
  [17] PHY_PMA_ISO_XCVR_CTRL_1 rw — Drives rx_termination PMA input for the associated lane when in PMA isolation mode or PHY isolation mode and lane is configured for Raw SerDes mode.
  [15:8] PHY_PMA_PI_POS_15_8 ro — Current value of rx_pi_val PMA output for the associated lane.
  [7:0] PHY_PMA_PI_POS_7_0 ro — Current value of rx_eye_plot_pi_val PMA output for the associated lane.
0xF008 WIZ16B8M4CT2_PHY_PMA_ISO_TX_LPC_HI__PHY_PMA_ISO_TX_LPC_LO access per field — PMA transmitter local preset coefficient low isolation register
  [31] PHY_PMA_ISO_TX_LPC_HI_15 ro — Current value of tx_local_preset_coef_valid PMA output for the associated lane.
  [28] PHY_PMA_ISO_TX_LPC_HI_12 rw — Drives tx_get_local_preset_coef PMA input for the associated lane when in PMA isolation mode or PHY isolation mode and lane is configured for Raw SerDes mode.
  [27:24] PHY_PMA_ISO_TX_LPC_HI_11_8 rw — Drives tx_local_preset_index PMA input for the associated lane when in PMA isolation mode or PHY isolation mode and lane is configured for Raw SerDes mode.
  [21:16] PHY_PMA_ISO_TX_LPC_HI_5_0 ro — Value of tx_local_tx_preset_coef[17:12] PMA output for the associated lane captured upon assertion of tx_local_preset_coef_valid for the associated lane. Cleared upon read.
  [13:8] PHY_PMA_ISO_TX_LPC_LO_13_8 ro — Value of tx_local_tx_preset_coef[11:6] PMA output for the associated lane captured upon assertion of tx_local_preset_coef_valid for the associated lane. Cleared upon read.
  [5:0] PHY_PMA_ISO_TX_LPC_LO_5_0 ro — Value of tx_local_tx_preset_coef[5:0] PMA output for the associated lane captured upon assertion of tx_local_preset_coef_valid for the associated lane. Cleared upon read.
0xF00C WIZ16B8M4CT2_PHY_PMA_ISO_TX_DMPH_HI__PHY_PMA_ISO_TX_DMPH_LO — PMA Tx de-emphasis low isolation register
  [21:16] PHY_PMA_ISO_TX_DMPH_HI_5_0 — Drives tx_deemphasis[17:12] PMA input for the associated lane when in PMA isolation mode or PHY isolation mode and lane is configured for Raw SerDes mode.
  [13:8] PHY_PMA_ISO_TX_DMPH_LO_13_8 — Drives tx_deemphasis[11:6] PMA input for the associated lane when in PMA isolation mode or PHY isolation mode and lane is configured for Raw SerDes mode.
  [5:0] PHY_PMA_ISO_TX_DMPH_LO_5_0 — Drives tx_deemphasis[5:0] PMA input for the associated lane when in PMA isolation mode or PHY isolation mode and lane is configured for Raw SerDes mode.
0xF010 WIZ16B8M4CT2_PHY_PMA_ISO_TX_MGN__PHY_PMA_ISO_TX_FSLF access per field reset 0x2D0F — PMA Tx FS/LF isolation register
  [24] PHY_PMA_ISO_TX_MGN_8 rw — Drives tx_low_power_swing_en PMA input for the associated lane when in PMA isolation mode or PHY isolation mode and lane is configured for Raw SerDes mode.
  [18:16] PHY_PMA_ISO_TX_MGN_2_0 rw — Drives tx_vmargin PMA input for the associated lane when in PMA isolation mode or PHY isolation mode and lane is configured for Raw SerDes mode.
  [13:8] PHY_PMA_ISO_TX_FSLF_13_8 ro — Current value of tx_local_fs PMA ouptut for the associated lane. (Not re-synchronized to apb_pclk)
  [5:0] PHY_PMA_ISO_TX_FSLF_5_0 ro — Current value of tx_local_lf PMA ouptut for the associated lane. (Not re-synchronized to apb_pclk)
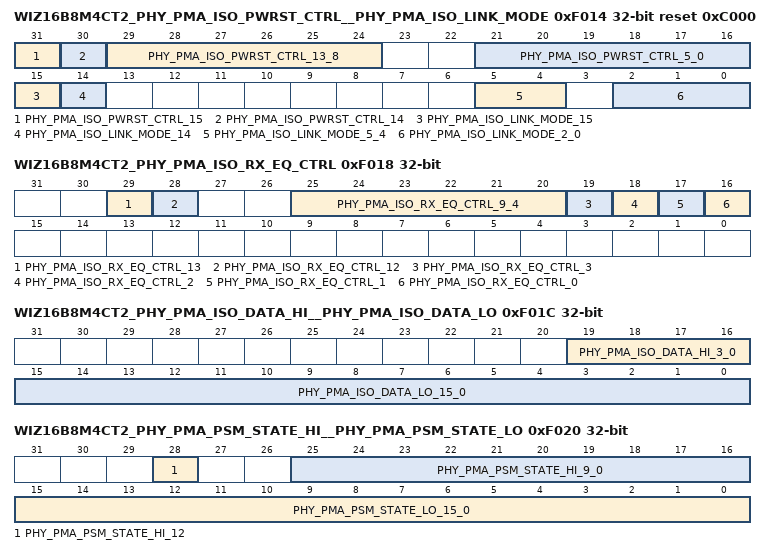
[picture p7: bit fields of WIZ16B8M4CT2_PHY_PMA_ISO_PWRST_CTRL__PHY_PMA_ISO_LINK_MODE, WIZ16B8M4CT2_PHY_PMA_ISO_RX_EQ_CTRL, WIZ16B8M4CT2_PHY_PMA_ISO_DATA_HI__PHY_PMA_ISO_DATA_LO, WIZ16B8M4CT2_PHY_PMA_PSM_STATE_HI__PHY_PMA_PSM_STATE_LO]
0xF014 WIZ16B8M4CT2_PHY_PMA_ISO_PWRST_CTRL__PHY_PMA_ISO_LINK_MODE access per field reset 0xC000 — PMA Isolation mode control register
  [31] PHY_PMA_ISO_PWRST_CTRL_15 rw — rx_sig_det_en_ext_ln_{nnnn} PMA input when in PMA isolation mode. (Used for PCIe)
  [30] PHY_PMA_ISO_PWRST_CTRL_14 rw — tx_cmn_mode_en_ext_ln_{nnnn} PMA input when in PMA isolation mode. (Used for PCIe)
  [29:24] PHY_PMA_ISO_PWRST_CTRL_13_8 ro — Current value of xcvr_power_state_ack_ln_{nnnn} PMA output.
  [21:16] PHY_PMA_ISO_PWRST_CTRL_5_0 rw — Drives xcvr_power_state_req_ln_{nnnn} PMA input when in PMA isolation mode or PHY isolation mode and lane is configured for Raw SerDes mode..
  [15] PHY_PMA_ISO_LINK_MODE_15 rw — tx_reset_n_ln_{nnnn} PMA input when in PMA isolation mode.
  [14] PHY_PMA_ISO_LINK_MODE_14 rw — rx_reset_n_ln_{nnnn} PMA input when in PMA isolation mode.
  [5:4] PHY_PMA_ISO_LINK_MODE_5_4 rw — Drives xcvr_standard_mode_ln_{nnnn} PMA input when in PMA isolation mode or PHY isolation mode and lane is configured for Raw SerDes mode.
  [2:0] PHY_PMA_ISO_LINK_MODE_2_0 rw — Drives xcvr_data_width_ln_{nnnn} PMA input when in PMA isolation mode or PHY isolation mode and lane is configured for Raw SerDes mode.
0xF018 WIZ16B8M4CT2_PHY_PMA_ISO_RX_EQ_CTRL access per field — PMA RX equalization control isolation register
  [29] PHY_PMA_ISO_RX_EQ_CTRL_13 rw — Drives rx_eq_training_data_valid PMA input for the associated lane when in PMA isolation mode or PHY isolation mode and lane is configured for Raw SerDes mode.
  [28] PHY_PMA_ISO_RX_EQ_CTRL_12 rw — Drives rx_eq_training PMA input for the associated lane when in PMA isolation mode or PHY isolation mode and lane is configured for Raw SerDes mode.
  [25:20] PHY_PMA_ISO_RX_EQ_CTRL_9_4 ro — The value of rx_link_eval_fb_dir_change PMA output for the associated lane upon assertion of rx_eq_eval_status to PMA. Cleared upon read.
  [19] PHY_PMA_ISO_RX_EQ_CTRL_3 ro — The value of rx_eq_eval_complete PMA output for the associated lane upon assertion of rx_eq_eval_status. Cleared upon read.
  [18] PHY_PMA_ISO_RX_EQ_CTRL_2 rw — Drives rx_invalid_request PMA input for the associated lane when in PMA isolation mode.
  [17] PHY_PMA_ISO_RX_EQ_CTRL_1 ro — Current value of rx_eq_eval_status PMA output for the associated lane.
  [16] PHY_PMA_ISO_RX_EQ_CTRL_0 rw — Drives rx_eq_eval PMA input for the associated lane when in PMA isolation mode or PHY isolation mode and lane is configured for Raw SerDes mode.
0xF01C WIZ16B8M4CT2_PHY_PMA_ISO_DATA_HI__PHY_PMA_ISO_DATA_LO ro — PMA low data isolation register
  [19:16] PHY_PMA_ISO_DATA_HI_3_0 — Current value of rx_rd[19:16] PMA output for the current lane. (Not re-synchronized to apb_pclk). This register can be written and the value will drive tx_td[19:16] for the associated lane when in PMA isolation mode or PHY isolation mode and lane is configured for Raw SerDes mode.
  [15:0] PHY_PMA_ISO_DATA_LO_15_0 — Current value of rx_rd[15:0] PMA output for the current lane. (Not re-synchronized to apb_pclk). This register can be written and the value will drive tx_td[15:0] for the associated lane when in PMA isolation mode or PHY isolation mode and lane is configured for Raw SerDes mode.
0xF020 WIZ16B8M4CT2_PHY_PMA_PSM_STATE_HI__PHY_PMA_PSM_STATE_LO ro — PMA PSM current state lower register
  [28] PHY_PMA_PSM_STATE_HI_12 — Current value of xcvr_psm_ready for the associated lane.
  [25:16] PHY_PMA_PSM_STATE_HI_9_0 — Current value of xcvr_psm_state[25:16] for the associated lane - PMA power state machine state. (Not re-synchronized to apb_pclk)
  [15:0] PHY_PMA_PSM_STATE_LO_15_0 — Current value of xcvr_psm_state[15:0] for the associated lane - PMA power state machine state. (Not re-synchronized to apb_pclk)
